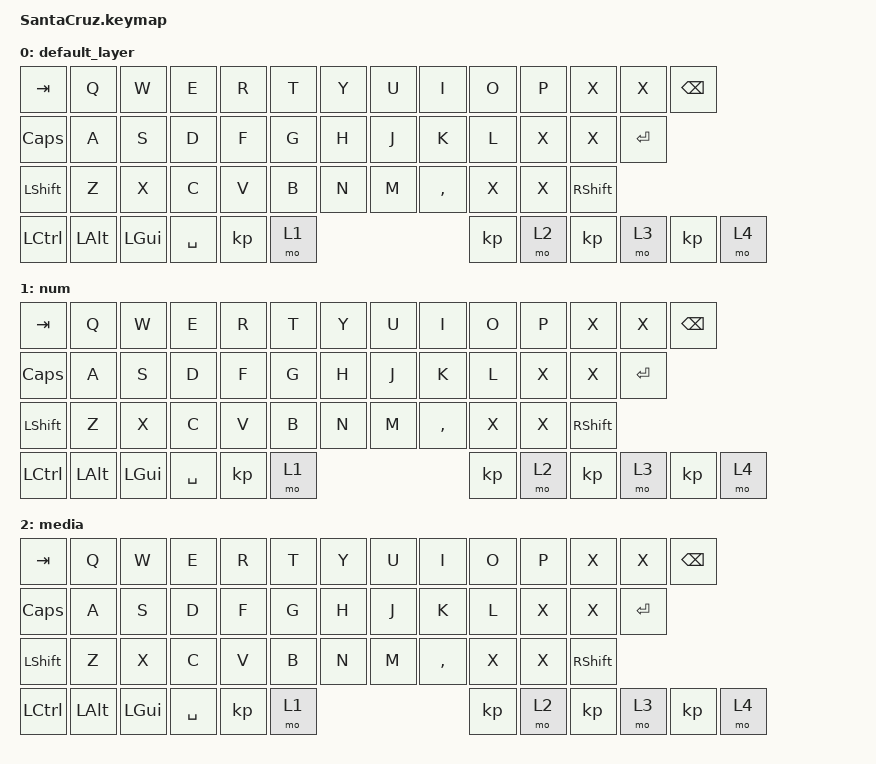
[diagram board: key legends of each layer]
/*
 * Copyright (c) 2020 The ZMK Contributors
 *
 * SPDX-License-Identifier: MIT
 */

#include <behaviors.dtsi>
#include <dt-bindings/zmk/bt.h>
#include <dt-bindings/zmk/keys.h>

/ {
    keymap {
        compatible = "zmk,keymap";

        default_layer {
            // ----------------------------------------------------------------------------------------------------------
            // |  ESC  |  1   |  2   |  3   |  4   |  5   |-------|-------|   6   |  7    |  8   |  9   |   0   | BSPC  |
            // |  TAB  |  Q   |  W   |  E   |  R   |  T   |-------|-------|   Y   |  U    |  I   |  O   |   P   |  \    |
            // | SHIFT |  A   |  S   |  D   |  F   |  G   |-------|-------|   H   |  J    |  K   |  L   |   ;   |  '    |
            // | CTRL  |  Z   |  X   |  C   |  V   |  B   |-------|-------|   N   |  M    |  ,   |  .   |   /   | ENTER |
            // |-------|ADJUST| LCTL | LALT | LGUI | LOWR | SPACE | SPACE |  RAIS | LEFT | DOWN | UARW  | RARW  |-------|

            bindings = <
&kp TAB   &kp Q      &kp W      &kp E      &kp R           &kp T           &kp Y            &kp U      &kp I       &kp O           &kp P           &kp X           &kp X          &kp BSPC
&kp CAPS  &kp A      &kp S      &kp D      &kp F           &kp G           &kp H            &kp J      &kp K       &kp L           &kp X           &kp X           &kp ENTER
&kp LSHFT &kp Z      &kp X      &kp C      &kp V           &kp B           &kp N            &kp M      &kp COMMA   &kp X           &kp X           &kp RSHIFT
&kp LCTRL  &kp LALT  &kp LGUI              &kp SPACE                                        &kp &mo 1  &kp &mo 2   &kp &mo 3       &kp &mo 4
            >;
        };

        num {
            // ----------------------------------------------------------------------------------------------------------
            // |  ESC  |  F2  |  F3  |  F4  |  F5  |  F6  |-------|-------|   F7  |  F8   |  F9  | F10  |  F11  |  F12  |
            // |   ~   |  !   |  @   |  #   |  $   |  %   |-------|-------|   ^   |   &   |  *   |  (   |   )   |  DEL  |
            // |       |  F1  |  F2  |  F3  |  F4  |  F5  |-------|-------|   F6  |   _   |  +   |  {   |   }   |   |   |
            // |       |  F7  |  F8  |  F9  |  F10 |  F11 |-------|-------|   F12 | LS(#) |LS(|) |      |       |       |
            // |-------|      |      |      |      |      |       |       |       | NEXT  | Vol- | Vol+ | PLAY  |-------|

            bindings = <
&kp TAB   &kp Q      &kp W      &kp E      &kp R           &kp T           &kp Y            &kp U      &kp I       &kp O           &kp P           &kp X           &kp X          &kp BSPC
&kp CAPS  &kp A      &kp S      &kp D      &kp F           &kp G           &kp H            &kp J      &kp K       &kp L           &kp X           &kp X           &kp ENTER
&kp LSHFT &kp Z      &kp X      &kp C      &kp V           &kp B           &kp N            &kp M      &kp COMMA   &kp X           &kp X           &kp RSHIFT
&kp LCTRL  &kp LALT  &kp LGUI              &kp SPACE                                        &kp &mo 1  &kp &mo 2   &kp &mo 3       &kp &mo 4
            >;
        };

        media {
            bindings = <
&kp TAB   &kp Q      &kp W      &kp E      &kp R           &kp T           &kp Y            &kp U      &kp I       &kp O           &kp P           &kp X           &kp X          &kp BSPC
&kp CAPS  &kp A      &kp S      &kp D      &kp F           &kp G           &kp H            &kp J      &kp K       &kp L           &kp X           &kp X           &kp ENTER
&kp LSHFT &kp Z      &kp X      &kp C      &kp V           &kp B           &kp N            &kp M      &kp COMMA   &kp X           &kp X           &kp RSHIFT
&kp LCTRL  &kp LALT  &kp LGUI              &kp SPACE                                        &kp &mo 1  &kp &mo 2   &kp &mo 3       &kp &mo 4
            >;
        };
    };
};
